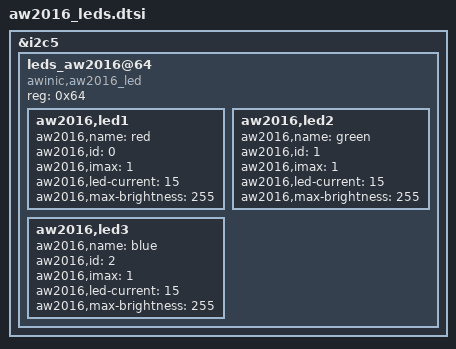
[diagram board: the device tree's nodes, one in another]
&i2c5 {
	leds_aw2016@64 {
	compatible = "awinic,aw2016_led";
	reg = <0x64>;

		aw2016,led1 {
			aw2016,name = "red";
			aw2016,id = <0>;
			aw2016,imax = <1>;      /* 0\1\2\3 = 15\30\5\10 mA */
			aw2016,led-current = <15>;      /* current = Imax*CUR/15 mA */
			aw2016,max-brightness = <255>;
		};

		aw2016,led2 {
			aw2016,name = "green";
			aw2016,id = <1>;
			aw2016,imax = <1>;
			aw2016,led-current = <15>;
			aw2016,max-brightness = <255>;
		};

		aw2016,led3 {
			aw2016,name = "blue";
			aw2016,id = <2>;
			aw2016,imax = <1>;
			aw2016,led-current = <15>;
			aw2016,max-brightness = <255>;
		};
	};
};
